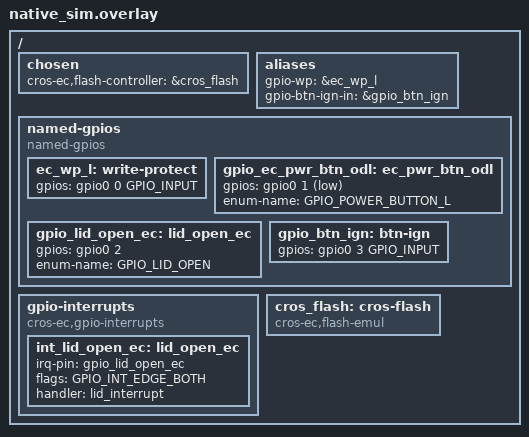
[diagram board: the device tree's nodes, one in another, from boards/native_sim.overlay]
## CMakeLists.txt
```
# Copyright 2026 The ChromiumOS Authors
# Use of this source code is governed by a BSD-style license that can be
# found in the LICENSE file.

cmake_minimum_required(VERSION 3.13.1)
find_package(Zephyr REQUIRED HINTS "${ZEPHYR_BASE}")
project(btn_ign_in)

target_sources(app PRIVATE src/test_btn_ign_in.c)
```

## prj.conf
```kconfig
# Copyright 2026 The ChromiumOS Authors
# Use of this source code is governed by a BSD-style license that can be
# found in the LICENSE file.

CONFIG_TEST=y
CONFIG_ZTEST=y
CONFIG_EMUL=y
CONFIG_FLASH=y
CONFIG_GPIO=y

CONFIG_CPP=y
CONFIG_STD_CPP20=y
CONFIG_REQUIRES_FULL_LIBCPP=y

CONFIG_CROS_EC=y
CONFIG_PLATFORM_EC=y
CONFIG_SHIMMED_TASKS=y
CONFIG_PLATFORM_EC_SWITCH=n
CONFIG_PLATFORM_EC_HOSTCMD=y

CONFIG_PLATFORM_EC_LID_SWITCH=y
CONFIG_PLATFORM_EC_BACKLIGHT_LID=n
CONFIG_PLATFORM_EC_POWER_BUTTON=y
```

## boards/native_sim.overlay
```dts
/* Copyright 2026 The ChromiumOS Authors
 * Use of this source code is governed by a BSD-style license that can be
 * found in the LICENSE file.
 */

#include <board-overlays/native_sim.dts>
#include <dt-bindings/gpio_defines.h>
#include <cros/binman.dtsi>

/ {
	chosen {
		cros-ec,flash-controller = &cros_flash;
	};

	aliases {
		gpio-wp = &ec_wp_l;
		gpio-btn-ign-in = &gpio_btn_ign;
	};

	named-gpios {
		compatible = "named-gpios";

		ec_wp_l: write-protect {
			gpios = <&gpio0 0 GPIO_INPUT>;
		};

		gpio_ec_pwr_btn_odl: ec_pwr_btn_odl {
			gpios = <&gpio0 1 (GPIO_ACTIVE_LOW | GPIO_INPUT | GPIO_PULL_UP)>;
			enum-name = "GPIO_POWER_BUTTON_L";
		};

		gpio_lid_open_ec: lid_open_ec {
			gpios = <&gpio0 2 (GPIO_INPUT | GPIO_PULL_UP)>;
			enum-name = "GPIO_LID_OPEN";
		};

		gpio_btn_ign: btn-ign {
			gpios = <&gpio0 3 GPIO_INPUT>;
		};
	};

	gpio-interrupts {
		compatible = "cros-ec,gpio-interrupts";

		int_lid_open_ec: lid_open_ec {
			irq-pin = <&gpio_lid_open_ec>;
			flags = <GPIO_INT_EDGE_BOTH>;
			handler = "lid_interrupt";
		};

	};

	cros_flash: cros-flash {
		compatible = "cros-ec,flash-emul";
	};
};
```

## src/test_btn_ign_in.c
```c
/* Copyright 2026 The ChromiumOS Authors
 * Use of this source code is governed by a BSD-style license that can be
 * found in the LICENSE file.
 */

#include "include/power_button.h"

#include <zephyr/drivers/gpio.h>
#include <zephyr/drivers/gpio/gpio_emul.h>
#include <zephyr/ztest.h>

static void assert_btn_ign(void)
{
	const struct gpio_dt_spec *gp_btn_ign =
		GPIO_DT_FROM_NODELABEL(gpio_btn_ign);

	zassert_ok(gpio_emul_input_set_dt(gp_btn_ign, 1),
		   "Failed to set BTN_IGN high");
}

static void deassert_btn_ign(void)
{
	const struct gpio_dt_spec *gp_btn_ign =
		GPIO_DT_FROM_NODELABEL(gpio_btn_ign);

	zassert_ok(gpio_emul_input_set_dt(gp_btn_ign, 0),
		   "Failed to set BTN_IGN low");
}

ZTEST(btn_ign_in, test_btn_ign_not_set)
{
	deassert_btn_ign();
	power_button_simulate_press(10000);
	zassert_equal(1, power_button_is_pressed(),
		      "Power button should not be ignored after 0s");
	k_sleep(K_SECONDS(1));
	zassert_equal(1, power_button_is_pressed(),
		      "Power button should not be ignored after 1s");
	k_sleep(K_SECONDS(4));
	zassert_equal(1, power_button_is_pressed(),
		      "Power button should not be ignored after 5s");
}

ZTEST(btn_ign_in, test_btn_ign_set)
{
	assert_btn_ign();
	power_button_simulate_press(10000);
	zassert_equal(0, power_button_is_pressed(),
		      "Power button should be ignored after 0s");
	k_sleep(K_SECONDS(3));
	zassert_equal(0, power_button_is_pressed(),
		      "Power button should be ignored after 3s");
	k_sleep(K_SECONDS(2));
	zassert_equal(1, power_button_is_pressed(),
		      "Power button should not be ignored after 5s");
}

ZTEST_SUITE(btn_ign_in, NULL, NULL, NULL, NULL, NULL);
```
